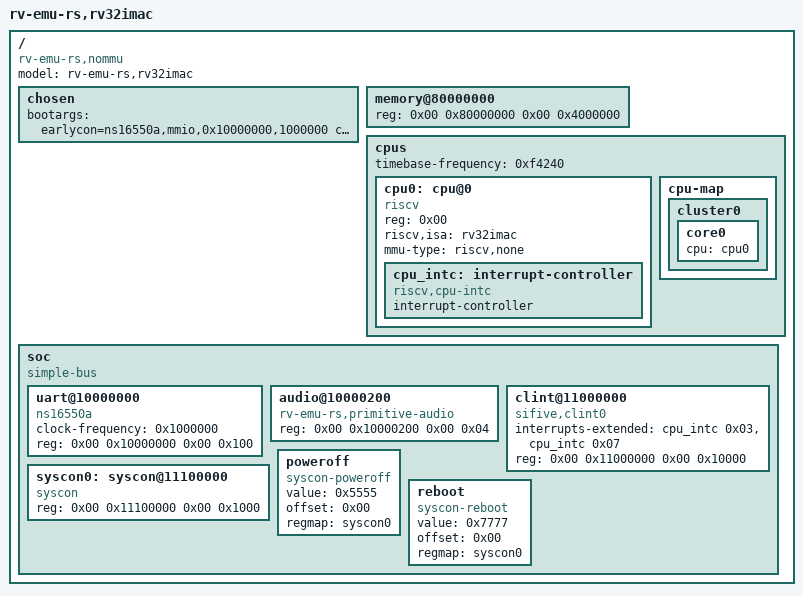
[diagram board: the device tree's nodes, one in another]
/dts-v1/;

/*
 * Device tree for rv-emu-rs, modelled on mini-rv32ima's sixtyfourmb.dts.
 *
 * Implemented memory map (src/bus.rs, src/clint.rs, src/syscon.rs,
 * src/uart.rs, src/primitive_audio.rs):
 *   0x10000000  UART, 16550-compatible byte registers at offsets 0-7
 *   0x10000200  audio, i16 samples written as halfwords
 *   0x11000000  CLINT: msip at offset 0x0, mtimecmp at 0x4000, mtime at 0xbff8
 *   0x11100000  syscon: poweroff (0x5555) and reboot (0x7777) at offset 0
 *   0x80000000  64 MiB of RAM
 *   0x83ffc000  device tree, loaded into the top 16 KiB of RAM by the emulator
 *
 * Build with: dtc -I dts -O dtb -o rv-emu-rs.dtb rv-emu-rs.dts
 */

/ {
	#address-cells = <0x02>;
	#size-cells = <0x02>;
	compatible = "rv-emu-rs,nommu";
	model = "rv-emu-rs,rv32imac";

	chosen {
		bootargs = "earlycon=ns16550a,mmio,0x10000000,1000000 console=ttyS0";
	};

	memory@80000000 {
		device_type = "memory";
		reg = <0x00 0x80000000 0x00 0x4000000>;
	};

	cpus {
		#address-cells = <0x01>;
		#size-cells = <0x00>;

		/* Clint::mtime() counts microseconds */
		timebase-frequency = <0xf4240>;

		cpu0: cpu@0 {
			device_type = "cpu";
			reg = <0x00>;
			status = "okay";
			compatible = "riscv";
			/* misa reads as 0x50001105 */
			riscv,isa = "rv32imac";
			mmu-type = "riscv,none";

			cpu_intc: interrupt-controller {
				#interrupt-cells = <0x01>;
				interrupt-controller;
				compatible = "riscv,cpu-intc";
			};
		};

		cpu-map {
			cluster0 {
				core0 {
					cpu = <&cpu0>;
				};
			};
		};
	};

	soc {
		#address-cells = <0x02>;
		#size-cells = <0x02>;
		compatible = "simple-bus";
		ranges;

		/*
		 * 16550-compatible byte registers at offsets 0-7. The interrupt
		 * line is not wired (there is no PLIC), so the driver falls back
		 * to polling. The binding requires interrupts; omitting it is
		 * the deviation until a PLIC exists.
		 */
		uart@10000000 {
			clock-frequency = <0x1000000>;
			reg = <0x00 0x10000000 0x00 0x100>;
			compatible = "ns16550a";
		};

		/* Halfword writes queue one 44100 Hz stereo i16 sample. */
		audio@10000200 {
			reg = <0x00 0x10000200 0x00 0x04>;
			compatible = "rv-emu-rs,primitive-audio";
		};

		clint@11000000 {
			interrupts-extended = <&cpu_intc 0x03 &cpu_intc 0x07>;
			reg = <0x00 0x11000000 0x00 0x10000>;
			compatible = "sifive,clint0", "riscv,clint0";
		};

		syscon0: syscon@11100000 {
			reg = <0x00 0x11100000 0x00 0x1000>;
			compatible = "syscon";
		};

		poweroff {
			value = <0x5555>;
			offset = <0x00>;
			regmap = <&syscon0>;
			compatible = "syscon-poweroff";
		};

		reboot {
			value = <0x7777>;
			offset = <0x00>;
			regmap = <&syscon0>;
			compatible = "syscon-reboot";
		};
	};
};
